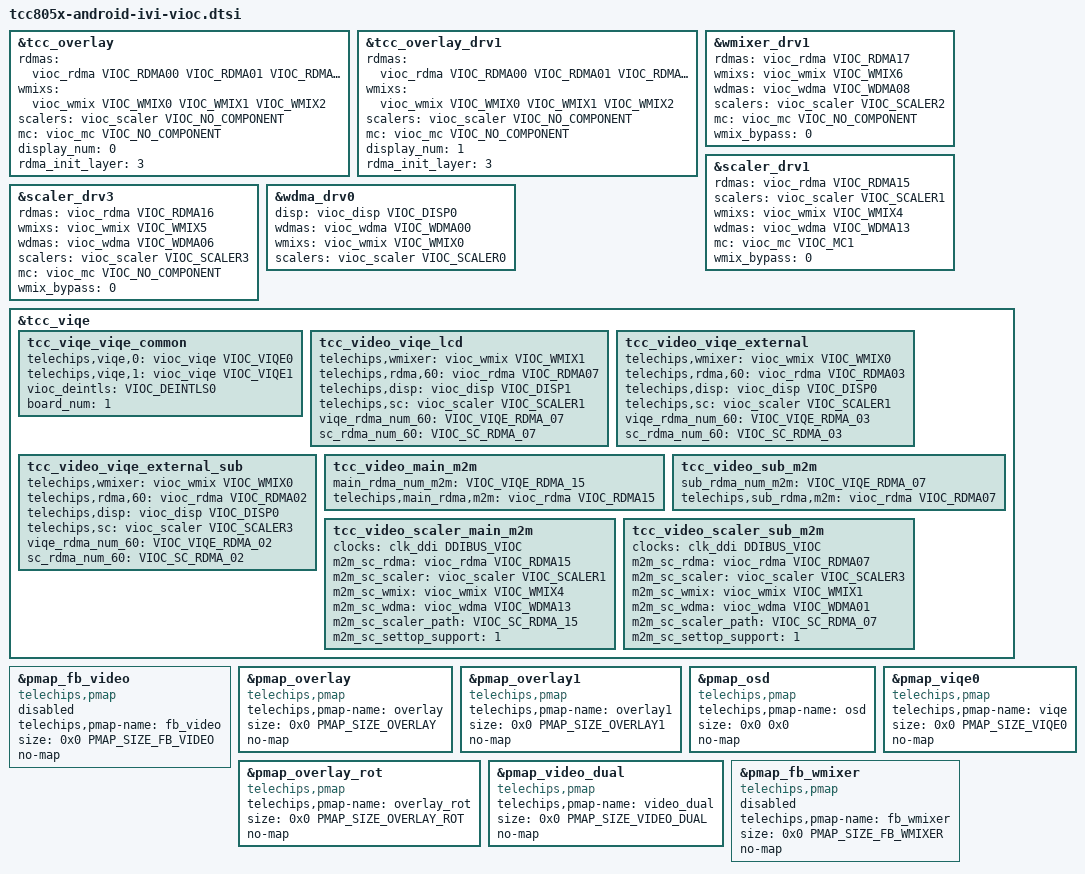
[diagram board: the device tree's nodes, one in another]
// SPDX-License-Identifier: (GPL-2.0-or-later OR MIT)
/*
 * Copyright (C) 2023 Telechips Inc.
 */

#include <dt-bindings/pmap/tcc805x/pmap-tcc805x-android-ivi-display.h>

/*=======================================================================================
 * TCC805x_Android_IVI VIOC PATH
 * -----------------------------
 *
 *            fb/drm: GRDMA00 ------------------- WMIX0 ------------ DISP0  (IVI)
 *       tcc_overlay: VRDMA03 ------------------+       +- SC0(4K) - WDMA00
 *
 *            HUD UI: GRDMA04 ------------------- WMIX1 ------------ DISP1  (HUD)
 *
 *      tcc_overlay1: VRDMA07 ------------------- WMIX2 ------------ DISP1 (CLUSTER)
 *    (Screen Share)
 *
 *             VIN02:   VIN02 --------- SC4(2K) -------------------- WDMA03
 *
 *             VIN03:   VIN03 --------- SC5(2K) -------------------- WDMA04
 *       scaler_drv1: VRDMA15 -(VIQE0)- SC1(4K) - WMIX4 ------------ WDMA13
 *
 *             VIN00:   VIN00 --------- SC6(2K) -------------------- WDMA05
 *       scaler_drv3: VRDMA16 --------- SC3(4K) - WMIX5 ------------ WDMA06
 *
 *             VIN01:   VIN01 --------- SC7(2K) -------------------- WDMA07
 *       wmixer_drv1: VRDMA17 --------- SC2(4K) - WMIX6 ------------ WDMA08
 *
 *=======================================================================================
 */
&tcc_overlay {
	rdmas = <&vioc_rdma VIOC_RDMA00 VIOC_RDMA01 VIOC_RDMA02 VIOC_RDMA03
						VIOC_RDMA04 VIOC_RDMA05 VIOC_RDMA06 VIOC_RDMA07
						VIOC_RDMA08 VIOC_RDMA09 VIOC_RDMA10 VIOC_RDMA11>;
	wmixs = <&vioc_wmix VIOC_WMIX0 VIOC_WMIX1 VIOC_WMIX2>;
	scalers = <&vioc_scaler VIOC_NO_COMPONENT>;
	mc = <&vioc_mc VIOC_NO_COMPONENT>;

	display_num = <0>;
	rdma_init_layer = <3>;

	status = "okay";
};

&tcc_overlay_drv1 {
	rdmas = <&vioc_rdma VIOC_RDMA00 VIOC_RDMA01 VIOC_RDMA02 VIOC_RDMA03
						VIOC_RDMA04 VIOC_RDMA05 VIOC_RDMA06 VIOC_RDMA07
						VIOC_RDMA08 VIOC_RDMA09 VIOC_RDMA10 VIOC_RDMA11>;
	wmixs = <&vioc_wmix VIOC_WMIX0 VIOC_WMIX1 VIOC_WMIX2>;
	scalers = <&vioc_scaler VIOC_NO_COMPONENT>;
	mc = <&vioc_mc VIOC_NO_COMPONENT>;

	display_num = <1>;
	rdma_init_layer = <3>;

	status = "okay";
};

&wmixer_drv1 {
	rdmas = <&vioc_rdma VIOC_RDMA17>;
	wmixs = <&vioc_wmix VIOC_WMIX6>;
	wdmas = <&vioc_wdma VIOC_WDMA08>;
	scalers = <&vioc_scaler VIOC_SCALER2>;
	mc = <&vioc_mc VIOC_NO_COMPONENT>;
	wmix_bypass = <0>;
	status = "okay";
};

&scaler_drv1 {
	rdmas = <&vioc_rdma VIOC_RDMA15>;
	scalers = <&vioc_scaler VIOC_SCALER1>;
	wmixs = <&vioc_wmix VIOC_WMIX4>;
	wdmas = <&vioc_wdma VIOC_WDMA13>;
	mc = <&vioc_mc VIOC_MC1>;
	wmix_bypass = <0>;
	status = "okay";
};

&scaler_drv3 {
	rdmas = <&vioc_rdma VIOC_RDMA16>;
	wmixs = <&vioc_wmix VIOC_WMIX5>;
	wdmas = <&vioc_wdma VIOC_WDMA06>;
	scalers = <&vioc_scaler VIOC_SCALER3>;
	mc = <&vioc_mc VIOC_NO_COMPONENT>;
	wmix_bypass = <0>;
	status = "okay";
};

&wdma_drv0 {
	disp = <&vioc_disp VIOC_DISP0>;
	wdmas = <&vioc_wdma VIOC_WDMA00>;
	wmixs = <&vioc_wmix VIOC_WMIX0>;
	scalers = <&vioc_scaler VIOC_SCALER0>;
	status = "okay";
};

&tcc_viqe {
	status = "okay";

	tcc_viqe_viqe_common {
		telechips,viqe,0 = <&vioc_viqe VIOC_VIQE0>;
		telechips,viqe,1 = <&vioc_viqe VIOC_VIQE1>;
		vioc_deintls = <VIOC_DEINTLS0>;
		board_num=<1>;
	};

	tcc_video_viqe_lcd {
		telechips,wmixer = <&vioc_wmix VIOC_WMIX1>;
		telechips,rdma,60 = <&vioc_rdma VIOC_RDMA07>;
		telechips,disp = <&vioc_disp VIOC_DISP1>;
		telechips,sc = <&vioc_scaler VIOC_SCALER1>;
		viqe_rdma_num_60 = <VIOC_VIQE_RDMA_07>;
		sc_rdma_num_60 = <VIOC_SC_RDMA_07>;
	};

	tcc_video_viqe_external {
		telechips,wmixer = <&vioc_wmix VIOC_WMIX0>;
		telechips,rdma,60 = <&vioc_rdma VIOC_RDMA03>;
		telechips,disp = <&vioc_disp VIOC_DISP0>;
		telechips,sc = <&vioc_scaler VIOC_SCALER1>;
		viqe_rdma_num_60 = <VIOC_VIQE_RDMA_03>;
		sc_rdma_num_60 = <VIOC_SC_RDMA_03>;
	};

	tcc_video_viqe_external_sub {
		telechips,wmixer = <&vioc_wmix VIOC_WMIX0>;
		telechips,rdma,60 = <&vioc_rdma VIOC_RDMA02>;
		telechips,disp = <&vioc_disp VIOC_DISP0>;
		telechips,sc = <&vioc_scaler VIOC_SCALER3>;
		viqe_rdma_num_60 = <VIOC_VIQE_RDMA_02>;
		sc_rdma_num_60 = <VIOC_SC_RDMA_02>;
	};

	tcc_video_main_m2m{
		main_rdma_num_m2m = <VIOC_VIQE_RDMA_15>;
		telechips,main_rdma,m2m = <&vioc_rdma VIOC_RDMA15>;
	};

	tcc_video_sub_m2m {
		sub_rdma_num_m2m = <VIOC_VIQE_RDMA_07>;
		telechips,sub_rdma,m2m = <&vioc_rdma VIOC_RDMA07>;
	};

	tcc_video_scaler_main_m2m {
		clocks = <&clk_ddi DDIBUS_VIOC>;
		m2m_sc_rdma = <&vioc_rdma VIOC_RDMA15>;
		m2m_sc_scaler = <&vioc_scaler VIOC_SCALER1>;
		m2m_sc_wmix = <&vioc_wmix VIOC_WMIX4>;
		m2m_sc_wdma = <&vioc_wdma VIOC_WDMA13>;
		m2m_sc_scaler_path = <VIOC_SC_RDMA_15>;
		m2m_sc_settop_support = <1>;
	};

	tcc_video_scaler_sub_m2m {
		clocks = <&clk_ddi DDIBUS_VIOC>;
		m2m_sc_rdma = <&vioc_rdma VIOC_RDMA07>;
		m2m_sc_scaler = <&vioc_scaler VIOC_SCALER3>;
		m2m_sc_wmix = <&vioc_wmix VIOC_WMIX1>;
		m2m_sc_wdma = <&vioc_wdma VIOC_WDMA01>;
		m2m_sc_scaler_path = <VIOC_SC_RDMA_07>;
		m2m_sc_settop_support = <1>;
	};
};

/*------------------------------------------------------------------------------
 * pmap
 *------------------------------------------------------------------------------
 */

&pmap_fb_video {
	compatible = "telechips,pmap";
	telechips,pmap-name = "fb_video";
	size = <0x0 PMAP_SIZE_FB_VIDEO>;
	no-map;
	status = "disabled";
};

&pmap_overlay {
	compatible = "telechips,pmap";
	telechips,pmap-name = "overlay";
	size = <0x0 PMAP_SIZE_OVERLAY>;
	no-map;
	status = "okay";
};

&pmap_overlay1 {
	compatible = "telechips,pmap";
	telechips,pmap-name = "overlay1";
	size = <0x0 PMAP_SIZE_OVERLAY1>;
	no-map;
	status = "okay";
};

&pmap_osd {
	compatible = "telechips,pmap";
	telechips,pmap-name = "osd";
	size = <0x0 0x0>;
	no-map;
	status = "okay";
};

&pmap_overlay_rot {
	compatible = "telechips,pmap";
	telechips,pmap-name = "overlay_rot";
	size = <0x0 PMAP_SIZE_OVERLAY_ROT>;
	no-map;
	status = "okay";
};

&pmap_viqe0 {
	compatible = "telechips,pmap";
	telechips,pmap-name = "viqe";
	size = <0x0 PMAP_SIZE_VIQE0>;
	no-map;
	status = "okay";
};

&pmap_video_dual {
	compatible = "telechips,pmap";
	telechips,pmap-name = "video_dual";
	size = <0x0 PMAP_SIZE_VIDEO_DUAL>;
	no-map;
	status = "okay";
};

&pmap_fb_wmixer {
	compatible = "telechips,pmap";
	telechips,pmap-name = "fb_wmixer";
	size = <0x0 PMAP_SIZE_FB_WMIXER>; //
	no-map;
	status = "disabled";
};

/* end of file */
